# R7FS3A17 register map
Vendor: Renesas; Series: S3; File version: 1.2
CPU: CM4 r0p1, little endian, MPU, FPU, VTOR, 4 interrupt priority bits
Registers are 8-bit, read-write, reset 0x0 unless marked. A register's access mark holds for its fields unless they carry their own. Offsets are from the block's base; [hi:lo] are bit positions; {n}, {i} and the like mark numbered series; 'fields as' and 'values as' point back to an identical list.

## PORT0 — Port 0 Control Registers
Base 0x40040000
Same registers: PORT5 0x400400A0, PORT6 0x400400C0, PORT7 0x400400E0, PORT8 0x40040100, PORT9 0x40040120
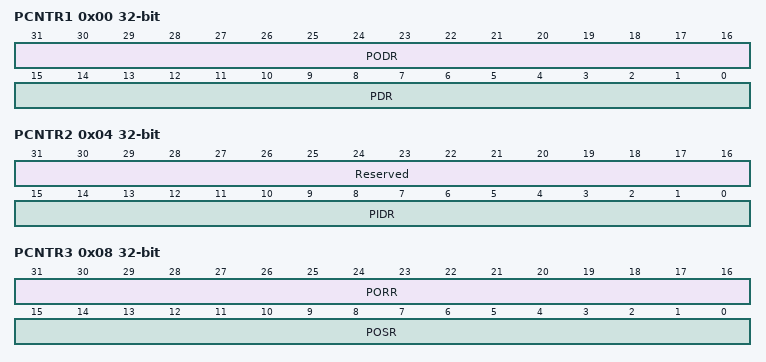
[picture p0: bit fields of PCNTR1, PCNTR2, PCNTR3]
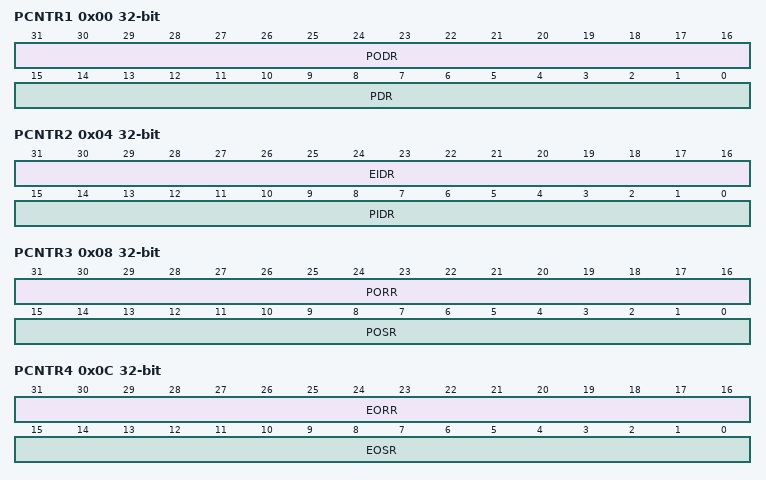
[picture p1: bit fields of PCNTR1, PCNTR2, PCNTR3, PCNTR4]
0x00 PCNTR1 32-bit — Port Control Register 1
  [31:16] PODR — Pmn Output Data
    0=Low output; 1=High output
  [15:0] PDR — Pmn Direction
    0=Input (functions as an input pin); 1=Output (functions as an output pin)
0x00 PODR 16-bit (alternate view of PCNTR1) — Output data register
  [15:0] PODR — Pmn Output Data
    0=Low output; 1=High output
0x02 PDR 16-bit (alternate view of PCNTR1) — Data direction register
  [15:0] PDR — Pmn Direction
    values as PCNTR1.PDR
0x04 PCNTR2 32-bit ro (reset mask 0xFFFF0000) — Port Control Register 2
  [31:16] Reserved — These bits are read as 0000000000000000.
  [15:0] PIDR — Pmn Input Data
    0=Low input; 1=High input
0x06 PIDR 16-bit ro reset not defined (alternate view of PCNTR2) — Input data register
  [15:0] PIDR — Pmn Input Data
    0=Low input; 1=High input
0x08 PCNTR3 32-bit wo — Port Control Register 3
  [31:16] PORR — Pmn Output Reset
    0=No affect to output; 1=Low output
  [15:0] POSR — Pmn Output Set
    0=No affect to output; 1=High output
0x08 PORR 16-bit wo (alternate view of PCNTR3) — Output reset register
  [15:0] PORR — Pmn Output Reset
    0=No affect to output; 1=Low output
0x0A POSR 16-bit wo (alternate view of PCNTR3) — Output set register
  [15:0] POSR — Pmn Output Set
    0=No affect to output; 1=High output

## PORT1 — Port 1 Control Registers
Base 0x40040020
Same registers: PORT2 0x40040040, PORT3 0x40040060, PORT4 0x40040080
0x00 PCNTR1 32-bit — Port Control Register 1
  [31:16] PODR — Pmn Output Data
    0=Low output; 1=High output
  [15:0] PDR — Pmn Direction
    0=Input (functions as an input pin); 1=Output (functions as an output pin)
0x00 PODR 16-bit (alternate view of PCNTR1) — Output data register
  [15:0] PODR — Pmn Output Data
    0=Low output; 1=High output
0x02 PDR 16-bit (alternate view of PCNTR1) — Data direction register
  [15:0] PDR — Pmn Direction
    values as PCNTR1.PDR
0x04 PCNTR2 32-bit ro (reset mask 0xFFFF0000) — Port Control Register 2
  [31:16] EIDR — Pmn Event Input Data
    0=Low input; 1=High input
  [15:0] PIDR — Pmn Input Data
    0=Low input; 1=High input
0x04 EIDR 16-bit ro (alternate view of PCNTR2) — Event input data register
  [15:0] EIDR — Pmn Event Input Data
    0=Low input; 1=High input
0x06 PIDR 16-bit ro reset not defined (alternate view of PCNTR2) — Input data register
  [15:0] PIDR — Pmn Input Data
    0=Low input; 1=High input
0x08 PCNTR3 32-bit wo — Port Control Register 3
  [31:16] PORR — Pmn Output Reset
    0=No affect to output; 1=Low output
  [15:0] POSR — Pmn Output Set
    0=No affect to output; 1=High output
0x08 PORR 16-bit wo (alternate view of PCNTR3) — Output set register
  [15:0] PORR — Pmn Output Reset
    0=No affect to output; 1=Low output
0x0A POSR 16-bit wo (alternate view of PCNTR3) — Output reset register
  [15:0] POSR — Pmn Output Set
    0=No affect to output; 1=High output
0x0C PCNTR4 32-bit — Port Control Register 4
  [31:16] EORR — Pmn Event Output Reset
    0=No affect to output; 1=Low output
  [15:0] EOSR — Pmn Event Output Set
    0=No affect to output; 1=High output
0x0C EORR 16-bit (alternate view of PCNTR4) — Event output set register
  [15:0] EORR — Pmn Event Output Reset
    0=No affect to output; 1=Low output
0x0E EOSR 16-bit (alternate view of PCNTR4) — Event output reset register
  [15:0] EOSR — Pmn Event Output Set
    0=No affect to output; 1=High output

## PMISC — Miscellaneous Port Control Register
Base 0x40040D00
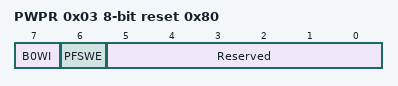
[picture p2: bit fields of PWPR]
0x03 PWPR reset 0x80 — Write-Protect Register
  [7] B0WI — PFSWE Bit Write Disable
    0=Writing to the PFSWE bit is enabled; 1=Writing to the PFSWE bit is disabled
  [6] PFSWE — PFS Register Write Enable
    0=Writing to the PFS register is disabled; 1=Writing to the PFS register is enabled
  [5:0] Reserved — These bits are read as 000000. The write value should be 000000.

## IWDT — Independent Watchdog Timer
Base 0x40044400
0x00 IWDTRR reset 0xFF — IWDT Refresh Register
  [7:0] IWDTRR — The counter is refreshed by writing 0x00 and then writing 0xFF to this register.
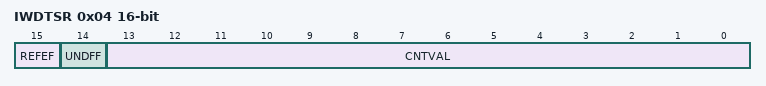
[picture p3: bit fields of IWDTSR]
0x04 IWDTSR 16-bit — IWDT Status Register
  [15] REFEF write-0-clears read-modifies — Refresh Error Flag
    0=Refresh error not occurred; 1=Refresh error occurred
  [14] UNDFF write-0-clears read-modifies — Underflow Flag
    0=Underflow not occurred; 1=Underflow occurred
  [13:0] CNTVAL ro — Counter Value Value counted by the counter

## DAC12 — 12-bit D/A converter
Base 0x4005E000
0x00 DADR0 16-bit — D/A Data Register 0
  [15:0] DADR — D/A Data Register NOTE: When DADPR.DPSEL = 0, the high-order 4 bits are fixed to 0: right justified format. When DADPR.DPSEL = 1, the low-order 4 bits are fixed to 0: left justified format.
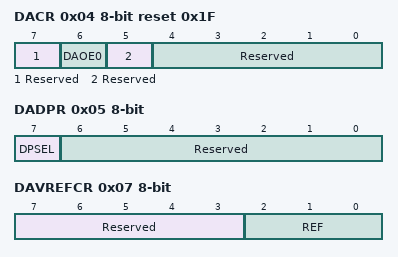
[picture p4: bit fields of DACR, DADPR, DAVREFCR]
0x04 DACR reset 0x1F — D/A Control Register
  [7] Reserved — This bit is read as 0. The write value should be 0.
  [6] DAOE0 — D/A Output Enable 0
    0=Analog output of channel 0 (DA0) is disabled; 1=D/A conversion of channel 0 is enabled. Analog output of channel 0 (DA0) is enabled.
  [5] Reserved — This bit is read as 0. The write value should be 0.
  [4:0] Reserved — These bits are read as 11111. The write value should be 11111.
0x05 DADPR — DADR0 Format Select Register
  [7] DPSEL — DADRm Format Select
    0=Right justified format; 1=Left justified format
  [6:0] Reserved — These bits are read as 0000000. The write value should be 0000000.
0x06 DAADSCR — D/A-A/D Synchronous Start Control Register
  [7] DAADST — D/A-A/D Synchronous Conversion
    0=D/A converter operation does not synchronize with A/D converter operation (unit 1) (countermeasure against interference between D/A and A/D conversions is disabled); 1=D/A converter operation synchronizes with A/D converter operation (unit 1) (countermeasure against interference between D/A and A/D conversions is enabled)
0x07 DAVREFCR — D/A VREF Control Register
  [7:3] Reserved — These bits are read as 00000. The write value should be 00000.
  [2:0] REF — D/A Reference Voltage Select
    0=Not selected; 1=AVCC0/AVSS0; 3=Internal reference voltage/AVSS0; 6=VREFH/VREFL; other=others (Setting prohibited)

## DAC8 — 8-bit D/A converter
Base 0x4009E000
{0x0+i} DACS{i} (i=0..1) — D/A Conversion Value Setting Register {i}
  [7:0] DACS — DACS D/A conversion store data note: When 8-bit D/A Converter output is selected as the reference input for the ACMPLP in the COMPSEL1 register, and ACMPLP operation is enabled (COMPMDR.CnENB = 1), changing the DACS[7:0] bits for the channel in use is prohibited.
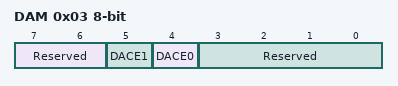
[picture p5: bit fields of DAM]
0x03 DAM — D/A Converter Mode Register
  [7:6] Reserved — These bits are read as 00. The write value should be 00.
  [5] DACE1 — D/A Operation Enable 1
    0=D/A conversion disabled for channel 1; 1=D/A conversion enabled for channel 1
  [4] DACE0 — D/A Operation Enable 0
    0=D/A conversion disabled for channel 0; 1=D/A conversion enabled for channel 0
  [3:0] Reserved — These bits are read as 0000. The write value should be 0000.

## TSN — Temperature Sensor
Base 0x407EC000
0x228 TSCDRL ro reset not defined — Temperature Sensor Calibration Data Register L
  [7:0] TSCDRL — The calibration data stores the lower 8 bits of the converted value.
0x229 TSCDRH ro reset not defined — Temperature Sensor Calibration Data Register H
  [7:0] TSCDRH — The calibration data stores the higher 8 bits of the converted value.
